AUTOSAR XML (schema 4-3-0)
package /Impl_CGW_ARPkg
  swc implementation Impl_SWC_CGW_type: programming-language=C, sw-version=1.0.0, vendor-id=0, behavior=SWC_CGW_type_IB
    code-descriptors:
      code SRC: artifact-descriptors=autosar-engineering-object={short-label=EngObject, category=SWSRC}
    resource consumption ResourceConsumption
      memory section MEM_SWC_CGW_CAL: size=0, sw-addrmethod=CAL, symbol=CAL
      memory section MEM_SWC_CGW_CODE: size=0, sw-addrmethod=CODE, symbol=CODE
package /SWC_CGW_ARPkg
  trigger interface IF_ExtTrig_CGW
    trigger Trig_CGW
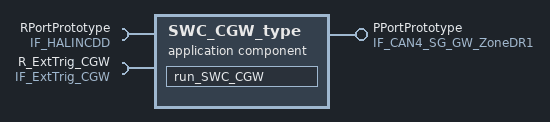
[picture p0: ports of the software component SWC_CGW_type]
  application sw component type SWC_CGW_type
    provide port PPortPrototype: provided-interface=IF_CAN4_SG_GW_ZoneDR1
    require port RPortPrototype: required-interface=IF_HALINCDD
    require port R_ExtTrig_CGW: required-interface=IF_ExtTrig_CGW
    behavior SWC_CGW_type_IB: handle-termination-and-restart=NO-SUPPORT
      external trigger occurred event ETE_CGW: start-on-event=run_SWC_CGW, trigger=R_ExtTrig_CGW.Trig_CGW
      runnable run_SWC_CGW
        data-read-access:
          access DataReadAccessName: accessed-variable=R_CAN1_FCM3.CAN1_SG_FCM3
        data-write-access:
          access DataWriteAccessName: accessed-variable=P_CAN1_APS1.CAN1_SG_FD_APS1
